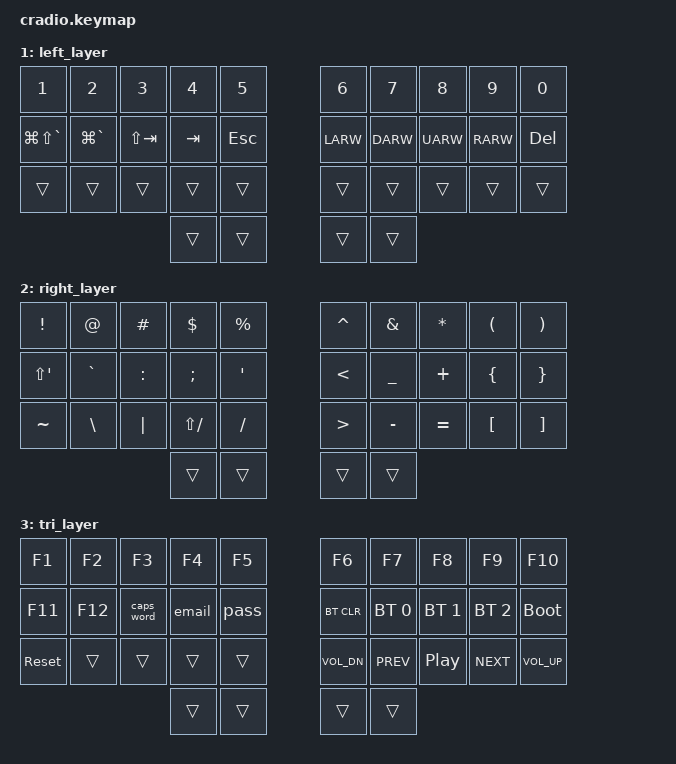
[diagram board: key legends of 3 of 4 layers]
// Copyright (c) 2022 The ZMK Contributors
// SPDX-License-Identifier: MIT

#include <behaviors.dtsi>
#include <dt-bindings/zmk/keys.h>
#include <dt-bindings/zmk/bt.h>

// Home row mods macro
#define HRML(k1,k2,k3,k4) &ht LSHFT k1  &ht LCTRL k2  &ht LALT k3  &ht LGUI k4
#define HRMR(k1,k2,k3,k4) &ht RGUI k1  &ht RALT k2  &ht RCTRL k3  &ht RSHFT k4

/ {
    behaviors {
        ht: hold_tap {
            compatible = "zmk,behavior-hold-tap";
            #binding-cells = <2>;
            flavor = "tap-preferred";
            tapping-term-ms = <300>;
            quick-tap-ms = <150>;
            require-prior-idle-ms = <100>;
            bindings = <&kp>, <&kp>;
        };
    };

    macros {
        email: email {
            compatible = "zmk,behavior-macro";
            #binding-cells = <0>;
            bindings
                = <&macro_tap &kp E>
                , <&macro_tap &kp M>
                , <&macro_tap &kp E>
                , <&macro_tap &kp R>
                , <&macro_tap &kp I>
                , <&macro_tap &kp C>
                , <&macro_tap &kp W>
                , <&macro_tap &kp A>
                , <&macro_tap &kp R>
                , <&macro_tap &kp N>
                , <&macro_tap &kp E>
                , <&macro_tap &kp Z>
                , <&macro_tap &kp AT>
                , <&macro_tap &kp B>
                , <&macro_tap &kp I>
                , <&macro_tap &kp T>
                , <&macro_tap &kp S>
                , <&macro_tap &kp O>
                , <&macro_tap &kp F>
                , <&macro_tap &kp L>
                , <&macro_tap &kp O>
                , <&macro_tap &kp V>
                , <&macro_tap &kp E>
                , <&macro_tap &kp DOT>
                , <&macro_tap &kp C>
                , <&macro_tap &kp O>
                , <&macro_tap &kp M>
                ;
        };

        // Dummy password used when developing login forms
        pass: pass {
            compatible = "zmk,behavior-macro";
            #binding-cells = <0>;
            bindings
                = <&macro_tap &kp H>
                , <&macro_tap &kp E>
                , <&macro_tap &kp R>
                , <&macro_tap &kp E>
                , <&macro_tap &kp D>
                , <&macro_tap &kp I>
                , <&macro_tap &kp S>
                , <&macro_tap &kp E>
                , <&macro_tap &kp X>
                , <&macro_tap &kp N1>
                , <&macro_tap &kp EXCL>
                ;
        };
    };

    conditional_layers {
        compatible = "zmk,conditional-layers";
        tri_layer {
            if-layers = <1 2>;
            then-layer = <3>;
        };
    };

    keymap {
        compatible = "zmk,keymap";
        default_layer {
            bindings = <
        //╭──────────┬──────────┬──────────┬──────────┬──────────╮   ╭─────────-----------------─┬──────────┬──────────┬──────────┬──────────╮
        //│  Q       │  W       │  E       │  R       │  T       │   │  Y                        │  U       │  I       │  O       │  P       │
            &kp Q      &kp W      &kp E      &kp R      &kp T          &kp Y                      &kp U      &kp I      &kp O      &kp P
        //├──────────┼──────────┼──────────┼──────────┼──────────┤   ├─────────-----------------─┼──────────┼──────────┼──────────┼──────────┤
        //│  A       │  S       │  D       │  F       │  G       │   │  H                        │  J       │  K       │  L       │ Backspace│
            HRML(A,        S,         D,         F)     &kp G          &kp H                      HRMR(J,        K,         L,     BSPC)
        //├──────────┼──────────┼──────────┼──────────┼──────────┤   ├─────────-----------------─┼──────────┼──────────┼──────────┼──────────┤
        //│  Z       │  X       │  C       │  V       │  B       │   │  N                        │  M       │ , <      │ . >      │ Enter    │
            &kp Z      &kp X      &kp C      &kp V      &kp B          &kp N                      &kp M      &kp COMMA  &kp DOT    &kp RET
        //╰──────────┴──────────┴──────────┼──────────┼──────────┤   ├─────────-----------------─┼──────────┼──────────┴──────────┴──────────╯
                                             &lt 1 ESC &kp LSHIFT     &mt LG(LS(LA(LCTRL))) SPACE &lt 2 TAB
        //                                 ╰──────────┴──────────╯   ╰──────────-----------------┴──────────╯
            >;
        };

        left_layer {
            bindings = <
        //╭─────────-------─┬────────---──┬─────────-─┬──────────┬──────────╮   ╭──────────┬──────────┬──────────┬──────────┬──────────╮
        //│ 1               │  2          │  3        │  4       │  5       │   │ 6        │ 7        │ 8        │ 9        │  0       │
            &kp N1            &kp N2       &kp N3      &kp N4     &kp N5         &kp N6      &kp N7     &kp N8     &kp N9    &kp N0
        //├────────-------──┼────────---──┼─────────-─┼──────────┼──────────┤   ├──────────┼──────────┼──────────┼──────────┼──────────┤
        //│                 │             │           │ tab      │ escape   │   │ LEFT     │ DOWN     │ UP       │ RIGHT    │  DELETE  │
           &kp LG(LS(GRAVE)) &kp LG(GRAVE) &kp LS(TAB) &kp TAB    &kp ESC        &kp LARW   &kp DARW   &kp UARW   &kp RARW   &kp DEL
        //├─────────-------─┼──────────---┼──────────-┼──────────┼──────────┤   ├──────────┼──────────┼──────────┼──────────┼──────────┤
        //│                 │             │           │          │          │   │          │          │          │          │          │
           &trans            &trans        &trans      &trans     &trans         &trans     &trans     &trans     &trans     &trans
        //╰─────────-------─┴─────────---─┴──────────-┼──────────┼──────────┤   ├──────────┼──────────┼──────────┴──────────┴──────────╯
                                                       &trans     &trans         &trans     &trans
        //                                            ╰──────────┴──────────╯   ╰──────────┴──────────╯
            >;
        };

        right_layer {
            bindings = <
        //╭─────────---─┬──────────┬─────────------─┬─────────--─┬──────────╮   ╭─────────----─┬──────────┬──────────┬──────────┬──────────╮
        //│  !          │  @       │  #             │  $         │  %       │   │  ^           │  &       │  *       │  (       │  )       │
            &kp EXCL     &kp AT     &kp HASH         &kp DLLR     &kp PRCNT      &kp CARET      &kp AMPS   &kp ASTRK  &kp LPAR   &kp RPAR
        //├─────-───--──┼──────────┼────────------──┼─────────--─┼──────────┤   ├───────----───┼──────────┼──────────┼──────────┼──────────┤
        //│  "          │  `       │  #             │  ;         │  '       │   │  <           │  _       │  +       │  {       │  }       │
           &kp LS(SQT)   &kp GRAVE &kp COLON         &kp SEMICOLON &kp SQT       &kp LT         &kp UNDER  &kp PLUS   &kp LBRC   &kp RBRC
        //├─────────--─-┼──────────┼─────────------─┼────────--──┼──────────┤   ├─────────----─┼──────────┼──────────┼──────────┼──────────┤
        //│  ~          │ \        │  "|"           │ ?          │ /        │   │  >           │  -       │  =       │  [       │  ]       │
           &kp TILDE     &kp BSLH   &kp PIPE         &kp LS(FSLH) &kp FSLH       &kp GT         &kp MINUS  &kp EQUAL  &kp LBKT   &kp RBKT
        //╰─────────---─┴──────────┴──────------────┼────────--──┼──────────┤   ├─────────----─┼──────────┼──────────┴──────────┴──────────╯
                                                     &trans       &trans         &trans        &trans
        //                                          ╰─────────--─┴──────────╯   ╰────────----──┴──────────╯
            >;
        };

        tri_layer {
            bindings = <
        //╭──────────┬──────────┬──────────┬──────────┬──────────╮   ╭──────────--┬────────--──┬─────────--─┬──────────--┬──────────╮
        //│          │          │          │          │          │   │            │            │            │            │          │
           &kp F1     &kp F2     &kp F3     &kp F4     &kp F5         &kp F6       &kp F7       &kp F8       &kp F9       &kp F10
        //├──────────┼──────────┼──────────┼──────────┼──────────┤   ├─────────--─┼──────--────┼─────────--─┼─────────--─┼──────────┤
        //│          │          │          │          │          │   │            │            │            │            │BOOTLOADER│
            &kp F11    &kp F12   &caps_word &email     &pass          &bt BT_CLR   &bt BT_SEL 0 &bt BT_SEL 1 &bt BT_SEL 2 &bootloader
        //├──────────┼──────────┼──────────┼──────────┼──────────┤   ├─────────--─┼───--───────┼─────────--─┼─────────--─┼──────────┤
        //│          │          │          │          │          │   │            │            │            │            │          │
           &sys_reset &trans     &trans    &trans     &trans         &kp C_VOL_DN &kp C_PREV   &kp C_PP     &kp C_NEXT   &kp C_VOL_UP
        //╰──────────┴──────────┴──────────┼──────────┼──────────┤   ├─────────--─┼─────────--─┼─────────--─┴─────────--─┴──────────╯
                                             &trans     &trans         &trans      &trans
        //                                 ╰──────────┴──────────╯   ╰──────────--┴──────--────╯
            >;
        };
    };
};
